# headsail register map
Vendor: tuni.fi; File version: 1.0
CPU: other r1p0, little endian, no MPU, no FPU, vendor SysTick, 2 interrupt priority bits
Registers are 32-bit, read-write, no defined reset value unless marked. A register's access mark holds for its fields unless they carry their own. Offsets are from the block's base; [hi:lo] are bit positions; lines under a group give offsets from that group.

## mdio_map0
Base 0xFF600200
Same registers: mdio_map1 0xFF600400
0x00 mdio group
  0x00 MDIO_CTRL
    [2:0] MDIO_CTRL
  0x04 MDIO_DIV reset 0xA (reset mask 0x0)
    [7:0] MDIO_DIV
  0x08 MDIO_WR_DATA
    [15:0] MDIO_WR_DATA
  0x0C MDIO_RD_DATA ro
    [15:0] MDIO_RD_DATA
  0x10 MDIO_STATUS ro
    [0] MDIO_STATUS
  0x14 MDIO_ADDR_ON_PHY
    [4:0] MDIO_ADDR_ON_PHY
  0x18 MDIO_ADDR_PHY
    [4:0] MDIO_ADDR_PHY

## i2c
Base 0xFFF05000
0x00 registers group
  0x00 CLK_PRESCALER — Clock Prescale Register
    [15:0] PRE — Sets the clock prescaler by the value in PRE to achieve the desired I2C clock by dividing
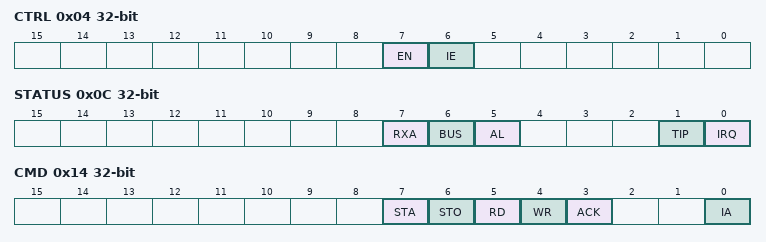
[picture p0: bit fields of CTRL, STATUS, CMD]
  0x04 CTRL — Control Register
    [7] EN — Enable the I2C peripheral.
    [6] IE — Enable interrupts
  0x08 RX ro — Receive Register
    [7:0] RX
  0x0C STATUS ro
    [7] RXA — Acknowledge from sent data
    [6] BUS — Bus is busy
    [5] AL — Arbitration lost.
    [1] TIP — Transfer in progress
    [0] IRQ — Interrupt received. This flag is always set when transmission has finished or bus arpitration was lostm, regardless of whether interrupts are enabled or not. This flag can possibly polled and is cleared by writing 1 to the IA command register.
  0x10 TX — Transmit Register
    [7:0] TX
  0x14 CMD — Command Register
    [7] STA — Send start bit
    [6] STO — Send stop bit
    [5] RD — Read from bus.
    [4] WR — Write to bus
    [3] ACK — Acknowledge received data
    [0] IA — Interrupt Acknowldge. Set to one to acknowledge interrupt. Cleared when transmission is done or arbitration is lost.

## spi_master0
Base 0xFFF02000
Same registers: spi_master1 0xFFF03000
0x00 registers group
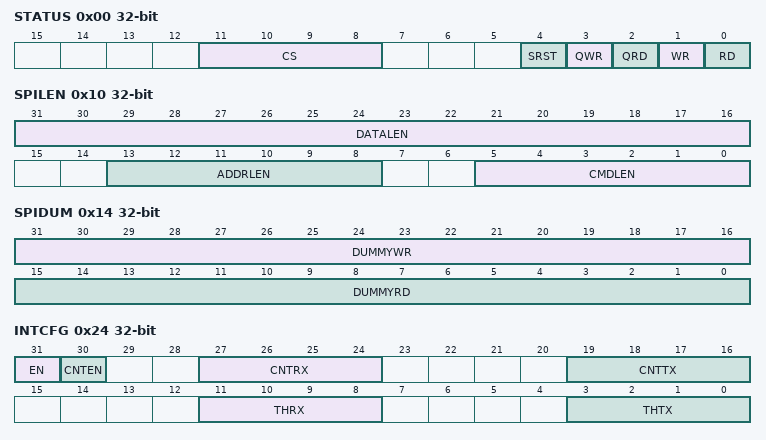
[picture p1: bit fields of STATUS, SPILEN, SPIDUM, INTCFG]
  0x00 STATUS
    [11:8] CS, [4] SRST, [3] QWR, [2] QRD, [1] WR, [0] RD
  0x04 CLKDIV — Clock Divider
    [7:0] CLKDIV
  0x08 SPICMD — SPI Command
  0x0C SPIADR — SPI Address
  0x10 SPILEN — SPI Transfer Length
    [31:16] DATALEN — The number of bits read or written. Note that first the SPI command and address are
    [13:8] ADDRLEN — The number of bits of the SPI address that should be sent.
    [5:0] CMDLEN — The number of bits of the SPI command that should be sent.
  0x14 SPIDUM — SPI Dummy Cycles
    [31:16] DUMMYWR — Dummy cycles (nothing being written or read) between sending the SPI command + SPI address and writing the data.
    [15:0] DUMMYRD — Dummy cycles (nothing being written or read) between sending the SPI command + SPI address and reading the data.
  0x18 TXFIFO wo — SPI Transmit FIFO
    [31:0] TX — Write data into the FIFO.
  0x20 RXFIFO ro — SPI Receive FIFO
    [31:0] RX — Read data from the FIFO.
  0x24 INTCFG — Interrupt Configuration
    [31] EN, [30] CNTEN, [27:24] CNTRX, [19:16] CNTTX, [11:8] THRX, [3:0] THTX
  0x28 INTSTA ro — This register isn't properly specified so we need to look at this

## uart0
Base 0xFFF00000
Same registers: uart1 0xFFF01000
0x00 registers group
  0x00 RBR_THR_DLL 8-bit — RBR receiver buffer, THR transmitter holding, DLL divisor latch LSB
  0x01 IER_DLM 8-bit — IER interrupt enable, DLM divisor latch MSB
  0x02 IIR_FCR 8-bit — IIR interrupt identification, FCR FIFO control
  0x03 LCR 8-bit — line control
  0x04 MCR 8-bit access not given — modem control (not used)
  0x05 LSR 8-bit ro — line status
  0x06 MSR 8-bit access not given — modem status (not used)
  0x07 SCR 8-bit access not given — scratch (not used)

## sdram_cfg
Base 0xFFD00000
0x00 axi_lite_regs group
  0x00 ddr_refresh_ack
  0x04 ddr_init_done
  0x08 axi_enabled reset 0x1 (reset mask 0x0)
  0x0C t_init reset 0x2710 (reset mask 0x0)
  0x10 t_arf reset 0x17C (reset mask 0x0)
  0x14 t_mrd reset 0x2 (reset mask 0x0)
  0x18 t_ras reset 0x3 (reset mask 0x0)
  0x1C t_rc reset 0x4 (reset mask 0x0)
  0x20 t_rcd reset 0x2 (reset mask 0x0)
  0x24 t_rfc reset 0x4 (reset mask 0x0)
  0x28 t_rp reset 0x2 (reset mask 0x0)
  0x2C t_rrd reset 0x1 (reset mask 0x0)
  0x30 t_wr reset 0x1 (reset mask 0x0)
  0x34 t_wtr reset 0x2 (reset mask 0x0)
  0x38 c_burst_len reset 0x1 (reset mask 0x0)
  0x3C c_burst_cycles reset 0x1 (reset mask 0x0)
  0x40 c_rd_lat reset 0x3 (reset mask 0x0)
  0x44 c_wr_lat reset 0x1 (reset mask 0x0)
  0x48 c_col_shift reset 0x1 (reset mask 0x0)
  0x4C c_col_mask reset 0x3FF (reset mask 0x0)
  0x50 c_row_shift reset 0xD (reset mask 0x0)
  0x54 c_row_mask reset 0x3FFF (reset mask 0x0)
  0x58 c_bank_shift reset 0xB (reset mask 0x0)
  0x5C c_bank_mask reset 0x3 (reset mask 0x0)
  0x60 c_offset
  0x64 c_start_addr
  0x68 c_end_addr reset 0xBFFFFFFF (reset mask 0x0)
  0x6C d_wrseparation
  0x70 d_wrlatcorr
